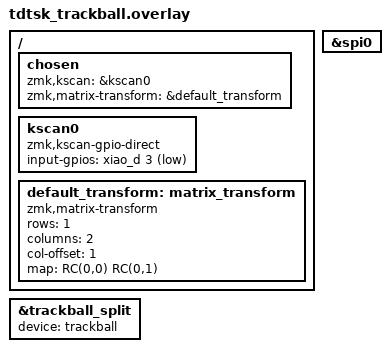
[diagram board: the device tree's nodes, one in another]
#include "tdtsk.dtsi"
#include "pmw3360.dtsi"
#include <dt-bindings/zmk/matrix_transform.h>

/ {
    chosen {
        zmk,kscan = &kscan0;
        zmk,matrix-transform = &default_transform;
    };

    kscan0: kscan0 {
        compatible = "zmk,kscan-gpio-direct";
        input-gpios = <&xiao_d 3 (GPIO_ACTIVE_LOW | GPIO_PULL_UP)>;
        status = "okay";
    };

    default_transform: matrix_transform {
        compatible = "zmk,matrix-transform";
        rows = <1>;
        columns = <2>;
		col-offset = <1>;
        map = <RC(0,0) RC(0,1)>;
    };
};

&trackball_split {
    device = <&trackball>;
};

&spi0 {
    status = "okay";
};

